AUTOSAR XML (schema 4-2-2)
package /ComponentTypes
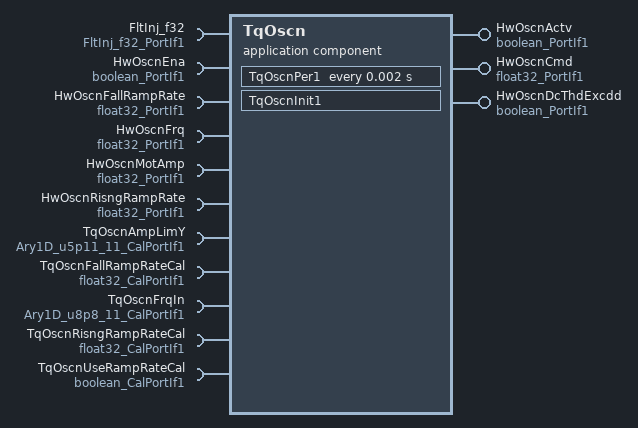
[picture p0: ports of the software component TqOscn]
  application sw component type TqOscn
    provide port HwOscnActv: nonqueued-sender-com-spec{data-element=Logl, init-value=FALSE}, provided-interface=boolean_PortIf1
    provide port HwOscnCmd: nonqueued-sender-com-spec{data-element=Val, init-value=0.0}, provided-interface=float32_PortIf1
    provide port HwOscnDcThdExcdd: nonqueued-sender-com-spec{data-element=Logl, init-value=FALSE}, provided-interface=boolean_PortIf1
    11 x require port:
      FltInj_f32: client-com-spec=Oper, required-interface=FltInj_f32_PortIf1
      HwOscnEna: nonqueued-receiver-com-spec{data-element=Logl, filter=data-filter-type=ALWAYS, init-value=0}, required-interface=boolean_PortIf1
      HwOscnFallRampRate: nonqueued-receiver-com-spec{data-element=Val, filter=data-filter-type=ALWAYS, init-value=-4400.0}, required-interface=float32_PortIf1
      HwOscnFrq: nonqueued-receiver-com-spec{data-element=Val, filter=data-filter-type=ALWAYS, init-value=50}, required-interface=float32_PortIf1
      HwOscnMotAmp: nonqueued-receiver-com-spec{data-element=Val, filter=data-filter-type=ALWAYS, init-value=0.0}, required-interface=float32_PortIf1
      HwOscnRisngRampRate: nonqueued-receiver-com-spec{data-element=Val, filter=data-filter-type=ALWAYS, init-value=4400.0}, required-interface=float32_PortIf1
      TqOscnAmpLimY: parameter-require-com-spec{init-value=[819, 922, 1024, 1126, 1229, 1331, 1434, 1434, 1434, 1434, 1434], parameter=Ary1D}, required-interface=Ary1D_u5p11_11_CalPortIf1
      TqOscnFallRampRateCal: parameter-require-com-spec{init-value=-4400.0, parameter=Val}, required-interface=float32_CalPortIf1
      TqOscnFrqIn: parameter-require-com-spec{init-value=[2560, 3200, 3840, 4480, 5120, 6400, 7680, 8960, 10240, 11520, 12800], parameter=Ary1D}, required-interface=Ary1D_u8p8_11_CalPortIf1
      TqOscnRisngRampRateCal: parameter-require-com-spec{init-value=4400.0, parameter=Val}, required-interface=float32_CalPortIf1
      TqOscnUseRampRateCal: parameter-require-com-spec{init-value=TRUE, parameter=Logl}, required-interface=boolean_CalPortIf1
    behavior TqOscn_InternalBehavior
      ar-typed-per-instance-memorys:
        14 x data, all with sw-calibration-access=READ-ONLY:
          AmpRampSt: type=float32
          dTqOscnNonZeroAmpFlg: type=boolean
          dTqOscnPreFinalCmd: type=float32
          dTqOscnRateLimdAmp: type=float32
          dTqOscnSinCmd: type=float32
          PreFinalCmdLpFil: type=FilLpRec1
          PrevActv: type=boolean
          PrevDcThdExcdd: type=boolean
          PrevEna: type=boolean
          PrevFallRampRate: type=float32
          PrevLimdAmp: type=float32
          PrevPhaAg: type=float32
          PrevPhaAgInc: type=float32
          PrevRisngRampRate: type=float32
      init event TqOscn_InitEvent: start-on-event=TqOscnInit1
      timing event TMT_TqOscnPer1: start-on-event=TqOscnPer1, period=0.002
      runnable TqOscnInit1
      runnable TqOscnPer1: minimum-start-interval=0.002
        data-receive-point-by-arguments:
          5 x access:
            REC_HwOscnFallRampRate_Val: accessed-variable=HwOscnFallRampRate.Val
            REC_HwOscnRisngRampRate_Val: accessed-variable=HwOscnRisngRampRate.Val
            REC_TqOscnAmp_Val: accessed-variable=HwOscnMotAmp.Val
            REC_TqOscnEna_Logl: accessed-variable=HwOscnEna.Logl
            REC_TqOscnFrq_Val: accessed-variable=HwOscnFrq.Val
        data-send-points:
          access SEND_HwOscnActv_Logl: accessed-variable=HwOscnActv.Logl
          access SEND_TqOscnCmd_Val: accessed-variable=HwOscnCmd.Val
          access SEND_TqOscnDcExcdd_Logl: accessed-variable=HwOscnDcThdExcdd.Logl
        sync call SC_FltInj_f32_Oper: operation=FltInj_f32.Oper, timeout=0
  swc implementation TqOscn_Implementation: behavior=TqOscn_InternalBehavior
    code-descriptors:
      code Default: artifact-descriptors=autosar-engineering-object={short-label=Default, category=SWSRC}
